VERSION ""

NS_ :

BS_:

BU_: XXX

BO_ 80 GW_50: 8 XXX
 SG_ SRS_CopilotBuckleSwitchStatus : 12|1@0+ (1,0) [0|1] "" XXX
 SG_ SRS_DriverBuckleSwitchStatus : 14|1@0+ (1,0) [0|1] "" XXX

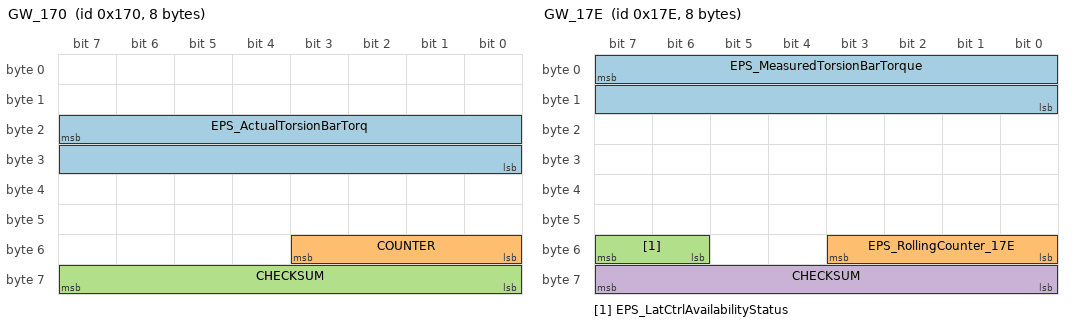
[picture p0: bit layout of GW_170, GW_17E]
BO_ 368 GW_170: 8 XXX
 SG_ EPS_ActualTorsionBarTorq : 23|16@0+ (0.001,-5.533) [0|250] "" XXX
 SG_ COUNTER : 51|4@0+ (1,0) [0|15] "" XXX
 SG_ CHECKSUM : 63|8@0+ (1,0) [0|255] "" XXX

BO_ 382 GW_17E: 8 XXX
 SG_ EPS_MeasuredTorsionBarTorque : 7|16@0- (0.001,0) [-65|65] "" XXX
 SG_ EPS_RollingCounter_17E : 51|4@0+ (1,0) [0|15] "" XXX
 SG_ EPS_LatCtrlAvailabilityStatus : 55|2@0+ (1,0) [0|3] "" XXX
 SG_ CHECKSUM : 63|8@0+ (1,0) [0|255] "" XXX

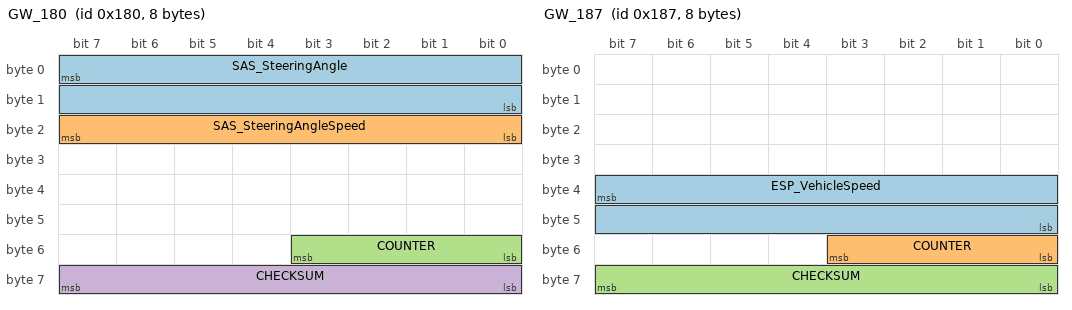
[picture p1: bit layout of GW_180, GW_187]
BO_ 384 GW_180: 8 XXX
 SG_ SAS_SteeringAngle : 7|16@0- (0.1,0) [-476|476] "deg" XXX
 SG_ SAS_SteeringAngleSpeed : 23|8@0+ (1,0) [0|255] "" XXX
 SG_ COUNTER : 51|4@0+ (1,0) [0|15] "" XXX
 SG_ CHECKSUM : 63|8@0+ (1,0) [0|255] "" XXX

BO_ 391 GW_187: 8 XXX
 SG_ ESP_VehicleSpeed : 39|16@0+ (0.05,0) [0|65535] "km/h" XXX
 SG_ COUNTER : 51|4@0+ (1,0) [0|15] "" XXX
 SG_ CHECKSUM : 63|8@0+ (1,0) [0|255] "" XXX

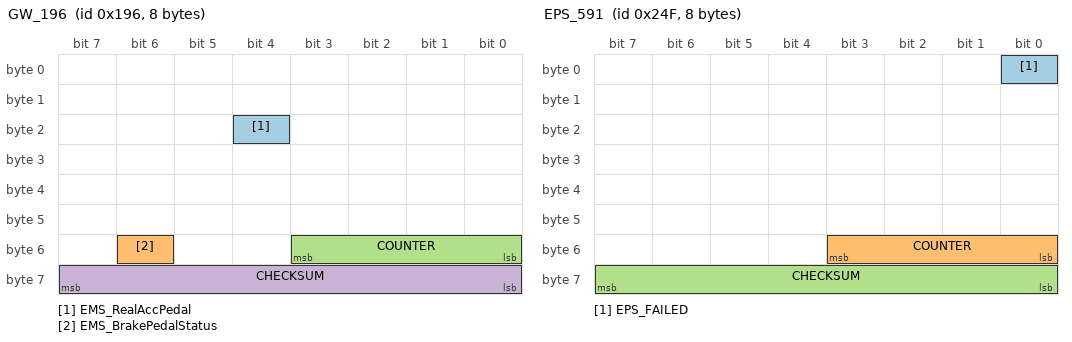
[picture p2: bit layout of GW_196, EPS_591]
BO_ 406 GW_196: 8 XXX
 SG_ EMS_RealAccPedal : 20|1@0+ (1,0) [0|1] "" XXX
 SG_ EMS_BrakePedalStatus : 54|1@0+ (1,0) [0|1] "" XXX
 SG_ COUNTER : 51|4@0+ (1,0) [0|15] "" XXX
 SG_ CHECKSUM : 63|8@0+ (1,0) [0|255] "" XXX

BO_ 442 GW_1BA: 32 XXX
 SG_ ACC_SteeringAngleSub_1BA : 7|16@0- (0.1,0) [-500|500] "deg" XXX
 SG_ ACC_SteeringAngleReq_1BA : 23|1@0+ (1,0) [0|1] "" XXX
 SG_ STEER_LIMIT_UP : 39|8@0+ (0.1,0) [0|25.5] "" XXX
 SG_ STEER_LIMIT_DOWN : 47|8@0+ (0.1,0) [-25.5|0] "" XXX
 SG_ ACC_RollingCounter_1BA : 51|4@0+ (1,0) [0|15] "" XXX
 SG_ CHECKSUM : 63|8@0+ (1,0) [0|255] "" XXX
 SG_ COUNTER_1 : 115|4@0+ (1,0) [0|15] "" XXX
 SG_ CHECKSUM_1 : 127|8@0+ (1,0) [0|255] "" XXX
 SG_ COUNTER_2 : 179|4@0+ (1,0) [0|15] "" XXX
 SG_ CHECKSUM_2 : 191|8@0+ (1,0) [0|255] "" XXX
 SG_ COUNTER_3 : 243|4@0+ (1,0) [0|15] "" XXX
 SG_ CHECKSUM_3 : 255|8@0+ (1,0) [0|255] "" XXX

BO_ 580 GW_244: 32 XXX
 SG_ ACC_Acceleration_24E : 7|16@0- (0.001,0) [-10|10] "m/s2" XXX
 SG_ ACC_AEBCtrlType : 34|3@0+ (1,0) [0|7] "" XXX
 SG_ ACC_FCWPreWarning : 35|1@0+ (1,0) [0|1] "" XXX
 SG_ ACC_RollingCounter_24E : 51|4@0+ (1,0) [0|15] "" XXX
 SG_ ACC_ACCMode : 53|3@0+ (1,0) [0|7] "" XXX
 SG_ ACC_ACCEnable : 54|1@0+ (1,0) [0|1] "" XXX
 SG_ ACC_ACCReq : 55|1@0+ (1,0) [0|1] "" XXX
 SG_ CHECKSUM : 63|8@0+ (1,0) [0|255] "" XXX
 SG_ sig_099 : 64|16@0+ (1,0) [0|65535] "" XXX
 SG_ COUNTER_1 : 115|4@0+ (1,0) [0|15] "" XXX
 SG_ CHECKSUM_1 : 127|8@0+ (1,0) [0|255] "" XXX
 SG_ COUNTER_2 : 179|4@0+ (1,0) [0|15] "" XXX
 SG_ CHECKSUM_2 : 191|8@0+ (1,0) [0|255] "" XXX
 SG_ COUNTER_3 : 243|4@0+ (1,0) [0|15] "" XXX
 SG_ CHECKSUM_3 : 255|8@0+ (1,0) [0|255] "" XXX

BO_ 591 EPS_591: 8 XXX
 SG_ EPS_FAILED : 0|1@0+ (1,0) [0|1] "" XXX
 SG_ COUNTER : 51|4@0+ (1,0) [0|15] "" XXX
 SG_ CHECKSUM : 63|8@0+ (1,0) [0|255] "" XXX

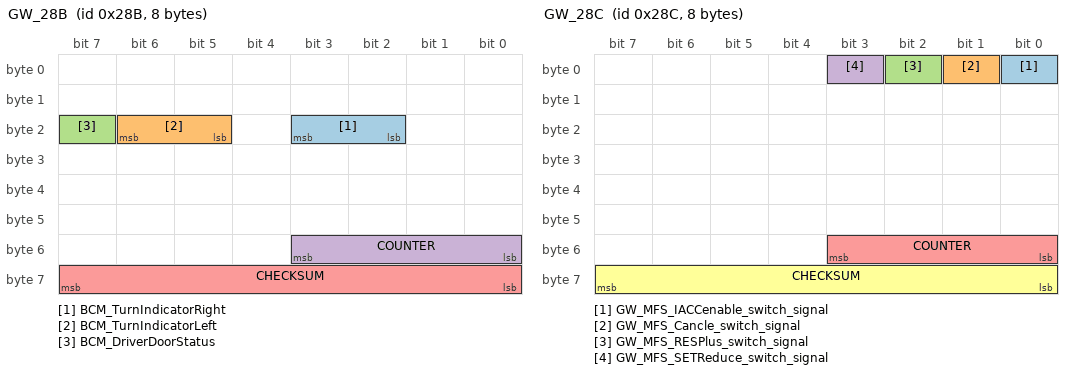
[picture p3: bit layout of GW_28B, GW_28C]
BO_ 651 GW_28B: 8 XXX
 SG_ BCM_TurnIndicatorRight : 19|2@0+ (1,0) [0|3] "" XXX
 SG_ BCM_TurnIndicatorLeft : 22|2@0+ (1,0) [0|3] "" XXX
 SG_ BCM_DriverDoorStatus : 23|1@0+ (1,0) [0|1] "" XXX
 SG_ COUNTER : 51|4@0+ (1,0) [0|15] "" XXX
 SG_ CHECKSUM : 63|8@0+ (1,0) [0|255] "" XXX

BO_ 652 GW_28C: 8 XXX
 SG_ GW_MFS_IACCenable_switch_signal : 0|1@0+ (1,0) [0|1] "" XXX
 SG_ GW_MFS_Cancle_switch_signal : 1|1@0+ (1,0) [0|1] "" XXX
 SG_ GW_MFS_RESPlus_switch_signal : 2|1@0+ (1,0) [0|1] "" XXX
 SG_ GW_MFS_SETReduce_switch_signal : 3|1@0+ (1,0) [0|1] "" XXX
 SG_ COUNTER : 51|4@0+ (1,0) [0|15] "" XXX
 SG_ CHECKSUM : 63|8@0+ (1,0) [0|255] "" XXX

BO_ 775 GW_307: 64 XXX
 SG_ ACC_SetSpeed : 7|16@0+ (0.0078125,-2) [0|65535] "" XXX
 SG_ ACC_DistanceLevel : 17|2@0+ (1,0) [0|3] "" XXX
 SG_ ACC_RollingCounter_35E : 51|4@0+ (1,0) [0|15] "" XXX
 SG_ CHECKSUM_1 : 63|8@0+ (1,0) [0|255] "" XXX
 SG_ COUNTER_2 : 115|4@0+ (1,0) [0|15] "" XXX
 SG_ CHECKSUM_2 : 127|8@0+ (1,0) [0|255] "" XXX
 SG_ COUNTER_3 : 179|4@0+ (1,0) [0|15] "" XXX
 SG_ CHECKSUM_3 : 191|8@0+ (1,0) [0|255] "" XXX
 SG_ COUNTER_4 : 243|4@0+ (1,0) [0|15] "" XXX
 SG_ CHECKSUM_4 : 255|8@0+ (1,0) [0|255] "" XXX
 SG_ COUNTER_5 : 307|4@0+ (1,0) [0|15] "" XXX
 SG_ CHECKSUM_5 : 319|8@0+ (1,0) [0|255] "" XXX
 SG_ COUNTER_6 : 371|4@0+ (1,0) [0|15] "" XXX
 SG_ CHECKSUM_6 : 383|8@0+ (1,0) [0|255] "" XXX
 SG_ COUNTER_7 : 435|4@0+ (1,0) [0|15] "" XXX
 SG_ CHECKSUM_7 : 447|8@0+ (1,0) [0|255] "" XXX
 SG_ COUNTER_8 : 499|4@0+ (1,0) [0|15] "" XXX
 SG_ CHECKSUM_8 : 511|8@0+ (1,0) [0|255] "" XXX

BO_ 794 GW_31A: 64 XXX
 SG_ STEER_PRESSED : 1|1@0+ (1,0) [0|1] "" XXX
 SG_ ACC_IACCHWAEnable : 2|1@0+ (1,0) [0|1] "" XXX
 SG_ ACC_IACCHWAMode : 9|2@0+ (1,0) [0|3] "" XXX
 SG_ ACC_RollingCounter_36D : 51|4@0+ (1,0) [0|15] "" XXX
 SG_ CHECKSUM_1 : 63|8@0+ (1,0) [0|255] "" XXX
 SG_ COUNTER_2 : 115|4@0+ (1,0) [0|15] "" XXX
 SG_ CHECKSUM_2 : 127|8@0+ (1,0) [0|255] "" XXX
 SG_ COUNTER_3 : 179|4@0+ (1,0) [0|15] "" XXX
 SG_ CHECKSUM_3 : 191|8@0+ (1,0) [0|255] "" XXX
 SG_ COUNTER_4 : 243|4@0+ (1,0) [0|15] "" XXX
 SG_ CHECKSUM_4 : 255|8@0+ (1,0) [0|255] "" XXX
 SG_ COUNTER_5 : 307|4@0+ (1,0) [0|15] "" XXX
 SG_ CHECKSUM_5 : 319|8@0+ (1,0) [0|255] "" XXX
 SG_ COUNTER_6 : 371|4@0+ (1,0) [0|15] "" XXX
 SG_ CHECKSUM_6 : 383|8@0+ (1,0) [0|255] "" XXX
 SG_ COUNTER_7 : 435|4@0+ (1,0) [0|15] "" XXX
 SG_ CHECKSUM_7 : 447|8@0+ (1,0) [0|255] "" XXX
 SG_ COUNTER_8 : 499|4@0+ (1,0) [0|15] "" XXX
 SG_ CHECKSUM_8 : 511|8@0+ (1,0) [0|255] "" XXX

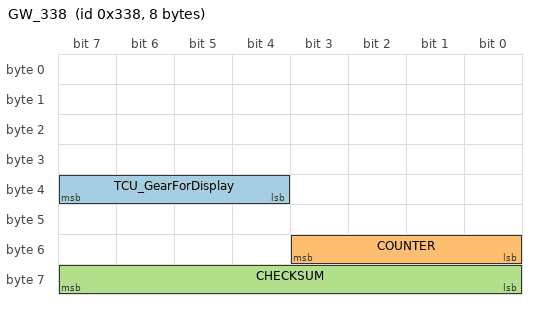
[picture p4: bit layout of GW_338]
BO_ 824 GW_338: 8 XXX
 SG_ TCU_GearForDisplay : 39|4@0+ (1,-7) [0|15] "" XXX
 SG_ COUNTER : 51|4@0+ (1,0) [0|15] "" XXX
 SG_ CHECKSUM : 63|8@0+ (1,0) [0|255] "" XXX

CM_ SG_ 384 SAS_SteeringAngle "1";
VAL_ 824 TCU_GearForDisplay 2 "N" 1 "R" 3 "D" 0 "P";
